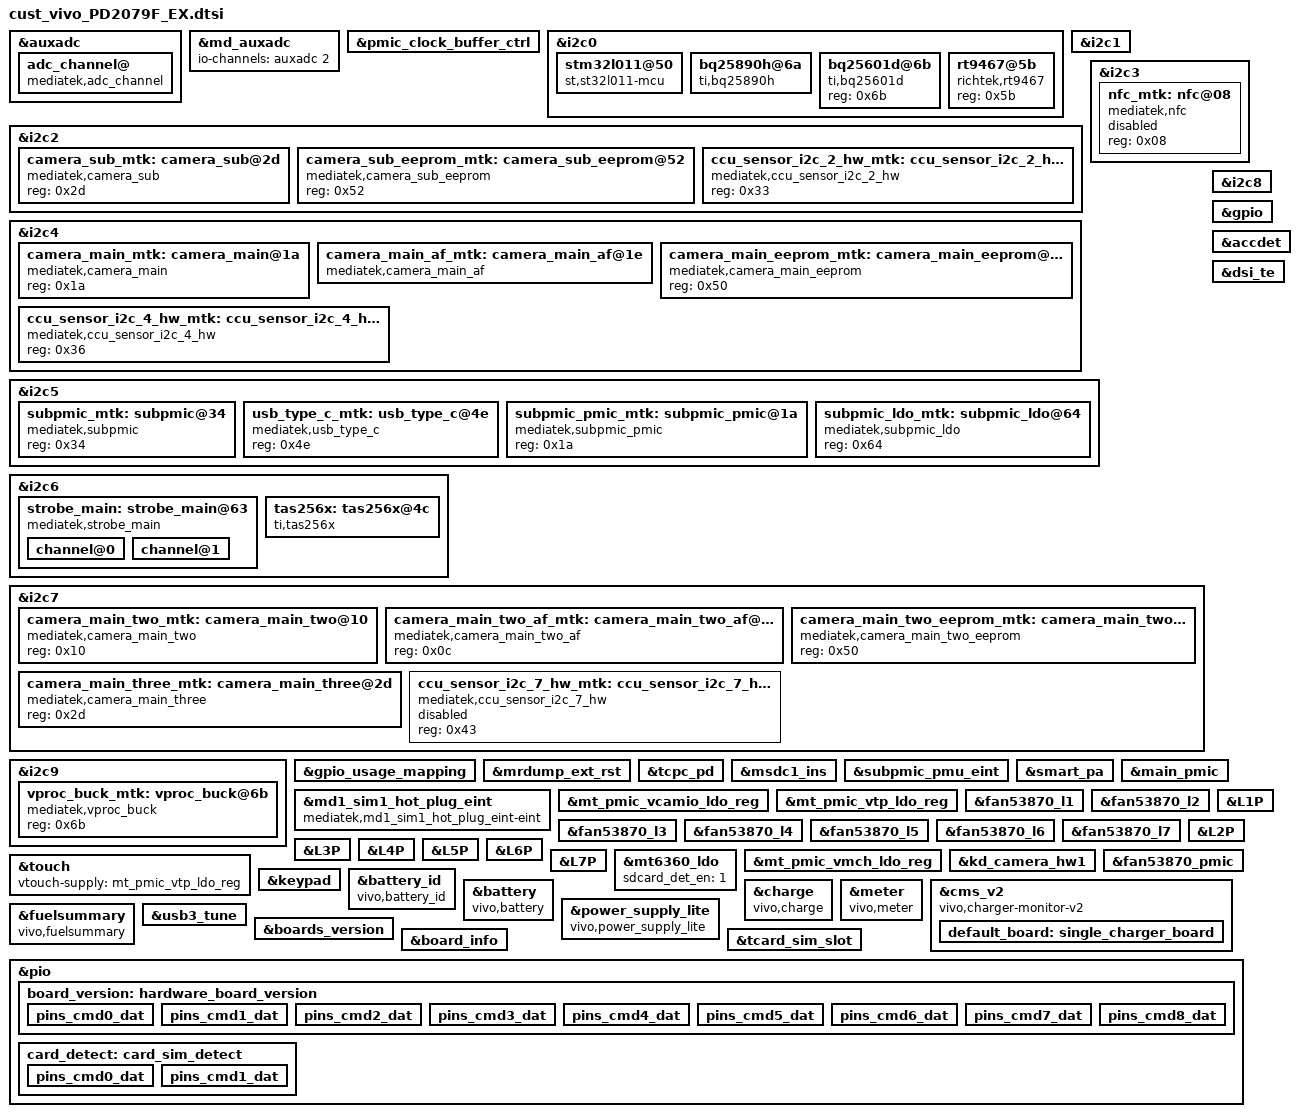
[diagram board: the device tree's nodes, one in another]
/*
 * Generated by MTK SP DrvGen Version: 3.5.160809 for MT6785.
 * 2020-11-23 11:59:31
 * Do Not Modify The File.
 * Copyright Mediatek Inc. (c) 2016.
*/

/*************************
 * ADC DTSI File
*************************/

&auxadc {
	adc_channel@ {
		compatible = "mediatek,adc_channel";
		mediatek,temperature0 = <0>;
		mediatek,temperature1 = <1>;
		mediatek,adc_fdd_rf_params_dynamic_custom_ch = <2>;
		status = "okay";
	};
};
&md_auxadc {
	io-channels = <&auxadc 2>;
};


/*************************
 * CLK_BUF DTSI File
*************************/

&pmic_clock_buffer_ctrl {
	mediatek,clkbuf-quantity = <7>;
	mediatek,clkbuf-config = <2 1 2 2 0 0 1>;
	mediatek,clkbuf-output-impedance = <4 4 4 4 0 0 4>;
	mediatek,clkbuf-controls-for-desense = <0 4 0 3 0 0 0>;
	status = "okay";
};


/*************************
 * I2C DTSI File
*************************/

&i2c0 {
	#address-cells = <1>;
	#size-cells = <0>;
	clock-frequency = <400000>;
	mediatek,use-open-drain;
};

&i2c1 {
	#address-cells = <1>;
	#size-cells = <0>;
	clock-frequency = <400000>;
	mediatek,use-open-drain;
};

&i2c2 {
	#address-cells = <1>;
	#size-cells = <0>;
	clock-frequency = <400000>;
	mediatek,use-open-drain;
	
	camera_sub_mtk:camera_sub@2d {
		compatible = "mediatek,camera_sub";
		reg = <0x2d>;
		status = "okay";
	};

	camera_sub_eeprom_mtk:camera_sub_eeprom@52 {
		compatible = "mediatek,camera_sub_eeprom";
		reg = <0x52>;
		status = "okay";
	};


	ccu_sensor_i2c_2_hw_mtk:ccu_sensor_i2c_2_hw@33 {
		compatible = "mediatek,ccu_sensor_i2c_2_hw";
		reg = <0x33>;
		status = "okay";
	};

};

&i2c3 {
	#address-cells = <1>;
	#size-cells = <0>;
	clock-frequency = <400000>;
	mediatek,use-open-drain;
	nfc_mtk:nfc@08 {
		compatible = "mediatek,nfc";
		reg = <0x08>;
		status = "disabled";
	};
	


	#include "fan53870.dtsi"
	#include "pm8008.dtsi"	

};

&i2c4 {
	#address-cells = <1>;
	#size-cells = <0>;
	clock-frequency = <1000000>;
	mediatek,use-open-drain;
	camera_main_mtk:camera_main@1a {
		compatible = "mediatek,camera_main";
		reg = <0x1a>;
		status = "okay";
	};

	camera_main_af_mtk:camera_main_af@1e {
		compatible = "mediatek,camera_main_af";
		reg = <0x1e>;
		status = "okay";
	};

	camera_main_eeprom_mtk:camera_main_eeprom@50 {
		compatible = "mediatek,camera_main_eeprom";
		reg = <0x50>;
		status = "okay";
	};



	ccu_sensor_i2c_4_hw_mtk:ccu_sensor_i2c_4_hw@36 {
		compatible = "mediatek,ccu_sensor_i2c_4_hw";
		reg = <0x36>;
		status = "okay";
	};

};

&i2c5 {
	#address-cells = <1>;
	#size-cells = <0>;
	clock-frequency = <3400000>;
	mediatek,use-push-pull;
	subpmic_mtk:subpmic@34 {
		compatible = "mediatek,subpmic";
		reg = <0x34>;
		status = "okay";
	};

	usb_type_c_mtk:usb_type_c@4e {
		compatible = "mediatek,usb_type_c";
		reg = <0x4e>;
		status = "okay";
	};

	subpmic_pmic_mtk:subpmic_pmic@1a {
		compatible = "mediatek,subpmic_pmic";
		reg = <0x1a>;
		status = "okay";
	};

	subpmic_ldo_mtk:subpmic_ldo@64 {
		compatible = "mediatek,subpmic_ldo";
		reg = <0x64>;
		status = "okay";
	};

};

/*
&i2c6 {
	#address-cells = <1>;
	#size-cells = <0>;
	clock-frequency = <400000>;
	mediatek,use-open-drain;
	i2c_lcd_bias_mtk:i2c_lcd_bias@73 {
		compatible = "mediatek,i2c_lcd_bias";
		reg = <0x73>;
		status = "okay";
	};

};
*/

&i2c6 {
	#address-cells = <1>;
	#size-cells = <0>;
	clock-frequency = <400000>;
	mediatek,use-open-drain;
	
	strobe_main: strobe_main@63 {
		compatible = "mediatek,strobe_main";
		reg = <0x63>;
		status = "okay";
	};
};

&i2c7 {
	#address-cells = <1>;
	#size-cells = <0>;
	clock-frequency = <400000>;
	mediatek,use-open-drain;
	
	camera_main_two_mtk:camera_main_two@10 {
		compatible = "mediatek,camera_main_two";
		reg = <0x10>;
		status = "okay";
	};

	camera_main_two_af_mtk:camera_main_two_af@0c {
		compatible = "mediatek,camera_main_two_af";
		reg = <0x0c>;
		status = "okay";
	};

	camera_main_two_eeprom_mtk:camera_main_two_eeprom@50 {
		compatible = "mediatek,camera_main_two_eeprom";
		reg = <0x50>;
		status = "okay";
	};

	camera_main_three_mtk:camera_main_three@2d {
		compatible = "mediatek,camera_main_three";
		reg = <0x2d>;
		status = "okay";
	};
	ccu_sensor_i2c_7_hw_mtk:ccu_sensor_i2c_7_hw@43 {
		compatible = "mediatek,ccu_sensor_i2c_7_hw";
		reg = <0x43>;
		status = "disabled";
	};

};

&i2c8 {
	#address-cells = <1>;
	#size-cells = <0>;
	clock-frequency = <400000>;
	mediatek,use-open-drain;
};

&i2c9 {
	#address-cells = <1>;
	#size-cells = <0>;
	clock-frequency = <3400000>;
	mediatek,use-open-drain;
	vproc_buck_mtk:vproc_buck@6b {
		compatible = "mediatek,vproc_buck";
		reg = <0x6b>;
		status = "okay";
	};

};



/*************************
 * GPIO DTSI File
*************************/

&gpio_usage_mapping {
	GPIO_FDD_BAND_SUPPORT_DETECT_1ST_PIN = <&pio 105 0>;
	GPIO_FDD_BAND_SUPPORT_DETECT_2ND_PIN = <&pio 106 0>;
	GPIO_FDD_BAND_SUPPORT_DETECT_3RD_PIN = <&pio 75 0>;
	GPIO_FDD_BAND_SUPPORT_DETECT_4TH_PIN = <&pio 107 0>;
	GPIO_SIM1_SIO = <&pio 128 0>;
	GPIO_SIM1_SRST = <&pio 129 0>;
	GPIO_SIM1_SCLK = <&pio 130 0>;
	GPIO_SIM2_SCLK = <&pio 131 0>;
	GPIO_SIM2_SRST = <&pio 132 0>;
	GPIO_SIM2_SIO = <&pio 133 0>;
	GPIO_SIM1_HOT_PLUG = <&pio 140 0>;
};

&gpio{
	gpio_init_default = <0 0 0 0 1 1 1>,
		<1 0 0 0 1 1 1>,
		<2 0 0 0 0 0 1>,
		<3 7 0 0 1 0 1>,
		<4 0 0 0 1 0 1>,
		<5 0 0 0 0 0 1>,
		<6 0 0 0 1 0 1>,
		<7 0 0 0 1 1 1>,
		<8 0 0 0 1 1 1>,
		<9 0 0 0 1 0 1>,
		<10 0 0 0 1 1 1>,
		<11 0 0 0 1 1 1>,
		<12 0 0 0 0 0 1>,
		<13 0 1 0 0 0 0>,
		<14 0 0 0 0 1 0>,
		<15 0 1 0 0 0 0>,
		<16 0 0 0 1 1 1>,
		<17 7 1 0 0 0 0>,
		<18 7 0 0 1 0 0>,
		<19 7 0 0 1 0 0>,
		<20 7 0 0 1 0 0>,
		<21 3 1 0 0 0 0>,
		<22 0 1 0 0 0 0>,
		<23 0 1 0 0 0 0>,
		<24 0 1 0 0 0 0>,
		<25 1 0 0 1 0 1>,
		<26 0 1 0 0 0 0>,
		<28 1 0 0 1 1 1>,
		<29 1 0 0 1 1 1>,
		<30 0 1 0 0 0 0>,
		<31 0 1 0 0 0 0>,
		<32 0 1 0 0 0 0>,
		<33 0 0 0 1 0 0>,
		<34 0 1 0 0 0 0>,
		<35 6 0 0 1 0 0>,
		<36 6 0 0 0 0 0>,
		<37 6 0 0 1 0 0>,
		<38 6 1 0 0 0 0>,
		<39 6 0 0 1 0 0>,
		<40 6 0 0 1 0 0>,
		<41 6 0 0 1 0 0>,
		<42 1 1 0 0 0 0>,
		<43 1 0 0 1 0 0>,
		<44 0 1 0 0 0 0>,
		<45 1 0 0 1 1 1>,
		<46 1 0 0 1 1 1>,
		<47 1 0 0 0 0 0>,
		<48 1 0 0 0 0 0>,
		<49 1 0 0 0 0 0>,
		<50 1 0 0 0 0 0>,
		<51 1 0 0 1 1 1>,
		<52 1 0 0 1 1 1>,
		<53 1 0 0 1 1 0>,
		<54 1 1 1 0 0 0>,
		<55 1 0 0 1 1 1>,
		<56 1 0 0 1 1 1>,
		<57 0 0 0 1 0 0>,
		<58 0 0 0 1 0 0>,
		<59 1 0 0 1 1 0>,
		<60 1 0 0 1 1 0>,
		<61 2 0 0 1 1 1>,
		<62 2 0 0 1 1 1>,
		<63 2 0 0 1 0 0>,
		<64 2 1 0 0 0 0>,
		<65 2 1 0 0 0 0>,
		<66 2 1 0 0 0 0>,
		<67 1 1 0 0 0 1>,
		<68 1 1 0 0 0 1>,
		<69 0 0 0 1 1 1>,
		<70 1 0 0 1 0 0>,
		<71 1 1 0 0 0 1>,
		<72 1 0 0 1 0 0>,
		<73 0 0 0 1 1 0>,
		<74 3 0 0 1 0 0>,
		<75 0 0 0 1 1 0>,
		<76 1 0 0 1 0 0>,
		<77 1 0 0 1 0 0>,
		<78 1 0 0 1 0 0>,
		<79 0 0 0 0 0 1>,
		<80 1 0 0 1 0 0>,
		<81 0 1 0 0 0 0>,
		<82 1 0 0 1 0 0>,
		<83 1 0 0 1 0 0>,
		<84 1 0 0 1 0 0>,
		<85 0 0 0 0 0 1>,
		<86 1 0 0 1 0 0>,
		<87 1 0 0 1 0 0>,
		<88 1 0 0 1 0 0>,
		<89 1 0 0 1 0 0>,
		<90 1 0 0 1 0 0>,
		<91 1 0 0 1 0 0>,
		<92 1 0 0 1 0 0>,
		<93 1 0 0 1 0 0>,
		<94 1 0 0 1 0 0>,
		<95 1 0 0 1 0 0>,
		<96 1 0 0 1 0 0>,
		<97 1 0 0 1 0 0>,
		<98 1 0 0 1 0 0>,
		<99 1 0 0 1 0 0>,
		<100 1 0 0 1 0 0>,
		<101 1 0 0 1 0 0>,
		<102 1 0 0 1 0 0>,
		<103 1 0 0 1 0 0>,
		<104 1 0 0 1 0 0>,
		<105 0 0 0 1 1 0>,
		<106 0 0 0 1 1 0>,
		<107 0 0 0 1 1 0>,
		<108 0 0 0 1 1 0>,
		<109 0 0 0 1 1 0>,
		<110 1 0 0 0 0 1>,
		<111 1 0 0 0 0 1>,
		<112 1 0 0 0 0 1>,
		<113 1 0 0 0 0 1>,
		<114 0 1 0 0 0 0>,
		<115 0 1 0 0 0 0>,
		<116 1 1 0 0 0 0>,
		<117 1 1 0 0 0 0>,
		<118 0 1 0 0 0 0>,
		<119 0 1 0 0 0 0>,
		<120 1 1 0 0 0 0>,
		<121 1 1 0 0 0 0>,
		<122 0 1 1 1 0 0>,
		<123 0 1 0 0 0 0>,
		<124 0 1 0 0 0 0>,
		<125 0 1 0 0 0 0>,
		<126 0 1 0 0 0 0>,
		<127 1 0 0 1 0 0>,
		<128 1 0 0 1 1 1>,
		<129 1 1 0 0 0 1>,
		<130 1 1 0 0 0 1>,
		<131 1 1 0 0 0 1>,
		<132 1 1 0 0 0 1>,
		<133 1 0 0 1 1 1>,
		<134 1 1 0 0 0 1>,
		<135 1 0 0 1 1 1>,
		<136 1 0 0 1 1 1>,
		<137 1 0 0 1 1 1>,
		<138 1 0 0 1 1 1>,
		<139 1 0 0 1 1 1>,
		<140 1 0 0 0 0 0>,
		<141 0 0 0 0 0 0>,
		<142 1 1 0 0 0 0>,
		<143 1 1 0 0 0 1>,
		<144 1 1 0 0 0 1>,
		<145 1 1 0 0 0 1>,
		<146 1 0 0 1 0 1>,
		<147 0 0 0 1 0 0>,
		<148 0 0 0 1 1 0>,
		<149 0 0 0 1 1 0>,
		<150 1 0 0 1 0 0>,
		<151 1 0 0 1 1 1>,
		<152 1 0 0 1 1 1>,
		<153 1 0 0 1 0 0>,
		<154 0 0 0 1 0 0>,
		<155 0 1 0 0 0 0>,
		<156 0 1 0 0 0 0>,
		<157 0 1 0 0 0 0>,
		<158 0 1 0 0 0 0>,
		<159 0 1 0 0 0 0>,
		<160 0 1 0 0 0 0>,
		<161 0 1 0 0 0 0>,
		<162 0 1 0 0 0 0>,
		<163 0 1 0 0 0 0>,
		<164 0 1 0 0 0 0>,
		<165 1 0 0 1 0 0>,
		<166 1 0 0 1 0 0>,
		<167 0 1 0 1 1 0>,
		<179 1 0 0 1 0 0>,
		<180 1 0 0 1 0 0>,
		<181 1 1 0 0 0 0>,
		<182 1 1 0 0 0 0>,
		<183 1 1 0 0 0 0>,
		<184 1 0 0 1 0 0>,
		<185 1 1 0 0 0 0>,
		<186 1 0 0 1 0 0>,
		<187 1 1 0 0 0 0>,
		<188 1 0 0 1 0 1>,
		<189 1 1 0 0 0 1>,
		<190 1 1 0 0 0 1>,
		<191 1 1 0 0 0 1>,
		<192 1 1 0 0 0 1>,
		<193 1 0 0 1 0 1>,
		<194 1 0 0 1 0 1>,
		<195 0 1 0 0 0 0>,
		<196 1 1 0 0 0 0>,
		<197 0 1 0 0 0 0>,
		<198 1 0 0 0 0 1>,
		<199 1 0 0 0 0 1>,
		<200 1 0 0 1 1 0>,
		<201 1 1 0 0 0 0>,
		<202 0 1 0 0 0 0>,
		<203 0 0 0 1 0 0>,
		<204 0 0 0 1 0 0>,
		<205 0 0 0 1 0 0>,
		<206 0 0 0 1 0 0>,
		<207 0 0 0 1 0 0>,
		<208 0 0 0 1 0 0>,
		<209 0 0 0 1 0 0>,
		<210 0 0 0 1 0 0>;
};


/*************************
 * EINT DTSI File
*************************/

#include <dt-bindings/interrupt-controller/irq.h>
#include <dt-bindings/interrupt-controller/arm-gic.h>

&mrdump_ext_rst {
	interrupt-parent = <&pio>;
	interrupts = <0 IRQ_TYPE_LEVEL_LOW 0 0>;
	deb-gpios = <&pio 0 0>;
	debounce = <512000>;
	status = "okay";
};

&accdet {
	interrupt-parent = <&pio>;
	interrupts = <9 IRQ_TYPE_LEVEL_LOW 9 0>,
					<1 IRQ_TYPE_LEVEL_LOW 1 0>;
	deb-gpios = <&pio 9 0>;
	deb-rgpios = <&pio 1 0>;
	debounce = <256000>;
	debounce1 = <256000>;
	status = "okay";
};

/*
&touch {
	interrupt-parent = <&pio>;
	interrupts = <1 IRQ_TYPE_EDGE_FALLING 1 0>;
	status = "okay";
};
*/

&tcpc_pd {
	interrupt-parent = <&pio>;
	interrupts = <7 IRQ_TYPE_EDGE_FALLING 7 0>;
	status = "okay";
};

&msdc1_ins {
	interrupt-parent = <&pio>;
	interrupts = <8 IRQ_TYPE_LEVEL_LOW 8 0>;
	status = "okay";
};

/*
&goodix_fp {
	interrupt-parent = <&pio>;
	interrupts = <3 IRQ_TYPE_EDGE_RISING 3 0>;
	status = "okay";
};
*/

&subpmic_pmu_eint {
	interrupt-parent = <&pio>;
	interrupts = <16 IRQ_TYPE_EDGE_FALLING 16 0>;
	status = "okay";
};

&dsi_te {
	interrupt-parent = <&pio>;
	interrupts = <43 IRQ_TYPE_EDGE_RISING 43 1>;
	status = "okay";
};

&smart_pa {
	interrupt-parent = <&pio>;
	interrupts = <69 IRQ_TYPE_LEVEL_LOW 69 0>;
	status = "okay";
};

&main_pmic {
	interrupt-parent = <&pio>;
	interrupts = <193 IRQ_TYPE_LEVEL_HIGH 209 0>;
	status = "okay";
};



/*************************
 * MD1_EINT DTSI File
*************************/

&md1_sim1_hot_plug_eint {
	compatible = "mediatek,md1_sim1_hot_plug_eint-eint";
	interrupts = <0 8>;
	debounce = <0 100000>;
	dedicated = <0 0>;
	src_pin = <0 1>;
	sockettype = <0 0>;
	status = "okay";
};



/*************************
 * PMIC DTSI File
*************************/

&mt_pmic_vcamio_ldo_reg {
	regulator-name = "vcamio";
	regulator-default-on = <1>; /* 0:skip, 1: off, 2:on */
	status = "okay";
};
&mt_pmic_vtp_ldo_reg {
	regulator-name = "vtp";
	regulator-default-on = <1>; /* 0:skip, 1: off, 2:on */
	status = "okay";
};
/* hope add fan53870 pmic start*/
&fan53870_l1 {
	regulator-name = "fan53870_l1";
	regulator-default-on = <1>; /* 0:skip, 1: off, 2:on */
	status = "okay";
};

&fan53870_l2 {
	regulator-name = "fan53870_l2";
	regulator-default-on = <1>; /* 0:skip, 1: off, 2:on */
	status = "okay";
};

&fan53870_l3 {
	regulator-name = "fan53870_l3";
	regulator-default-on = <1>; /* 0:skip, 1: off, 2:on */
	status = "okay";
};

&fan53870_l4 {
	regulator-name = "fan53870_l4";
	regulator-default-on = <1>; /* 0:skip, 1: off, 2:on */
	status = "okay";
};

&fan53870_l5 {
	regulator-name = "fan53870_l5";
	regulator-default-on = <1>; /* 0:skip, 1: off, 2:on */
	status = "okay";
};

&fan53870_l6 {
	regulator-name = "fan53870_l6";
	regulator-default-on = <1>; /* 0:skip, 1: off, 2:on */
	status = "okay";
};

&fan53870_l7 {
	regulator-name = "fan53870_l7";
	regulator-default-on = <1>; /* 0:skip, 1: off, 2:on */
	status = "okay";
};
/* hope add fan53870 pmic end*/

/* hope add pm8008 pmic start*/
&L1P {
	regulator-name = "pm8008_l1";
	regulator-default-on = <1>; /* 0:skip, 1: off, 2:on */
	status = "okay";

};

&L2P {
	regulator-name = "pm8008_l2";
	regulator-default-on = <1>; /* 0:skip, 1: off, 2:on */
	status = "okay";

};

&L3P {
	regulator-name = "pm8008_l3";
	regulator-default-on = <1>; /* 0:skip, 1: off, 2:on */
	status = "okay";

};

&L4P {
	regulator-name = "pm8008_l4";
	regulator-default-on = <1>; /* 0:skip, 1: off, 2:on */
	status = "okay";

};

&L5P {
	regulator-name = "pm8008_l5";
	regulator-default-on = <1>; /* 0:skip, 1: off, 2:on */
	status = "okay";

};

&L6P {
	regulator-name = "pm8008_l6";
	regulator-default-on = <1>; /* 0:skip, 1: off, 2:on */
	status = "okay";

};

&L7P {
	regulator-name = "pm8008_l7";
	regulator-default-on = <1>; /* 0:skip, 1: off, 2:on */
	status = "okay";

};
/* hope add pm8008 pmic end*/

/* hope add for mt6360 LDO5 use for af power, remove sdcard use LDO5 PMIC start */
&mt6360_ldo {
	sdcard_det_en = <1>;
};
&mt_pmic_vmch_ldo_reg {
	regulator-name = "VMCH";
	regulator-default-on = <1>; /* 0:skip, 1: off, 2:on */
	status = "okay";
};
/* hope add for mt6360 LDO5 use for af power, remove sdcard use LDO5 PMIC end */

&kd_camera_hw1 {
 
 	cam0_vcamio-supply = <&mt_pmic_vcamio_ldo_reg>;
	cam0_vcamd-supply = <&fan53870_l1>;
	cam0_vcamd_b-supply = <&L1P>;
	cam0_vcama-supply = <&fan53870_l3>;
	cam0_vcama_b-supply = <&L3P>;
	//cam0_vcamois-supply = <&fan53870_l6>;
	//cam0_vcamois_b-supply = <&L6P>;	
		
	cam1_vcamio-supply = <&mt_pmic_vcamio_ldo_reg>;
	cam1_vcamd-supply = <&fan53870_l2>;
	cam1_vcamd_b-supply = <&L2P>;
	cam1_vcama-supply = <&fan53870_l4>;
	cam1_vcama_b-supply = <&L4P>;
		
	cam2_vcamio-supply = <&mt_pmic_vcamio_ldo_reg>;
	cam2_vcama-supply = <&fan53870_l5>;
 	cam2_vcama_b-supply = <&L5P>;
	
	cam4_vcamio-supply = <&mt_pmic_vcamio_ldo_reg>;
	cam4_vcama-supply = <&fan53870_l5>;
	cam4_vcama_b-supply = <&L5P>;
		
	cam0_enable_sensor = "s5kgw3sp13pd2062_mipi_raw";
	cam1_enable_sensor = "s5kgh1sm24pd2062_mipi_raw";
        cam2_enable_sensor = "ov8856pd2062_mipi_raw";
        cam4_enable_sensor = "ov02b10pd2062_mipi_raw";
 
	status = "okay";
};

&fan53870_pmic {
	interrupt-parent = <&pio>;
	interrupts = <14 IRQ_TYPE_EDGE_RISING 14 0>;
	deb-gpios = <&pio 14 0>;
	debounce = <256000>;
	status = "okay";
};

&camera_main_af_mtk {
	vcamaf-supply = <&fan53870_l6>;
};
&strobe_main {
	decouple = <0>;
	channel@0 {
		type = <1>;
		ct = <0>;
		part = <0>;
	};
	channel@1 {
		type = <1>;
		ct = <1>;
		part = <0>;
	};
};


&touch {
	vtouch-supply = <&mt_pmic_vtp_ldo_reg>;
	status = "okay";
};


/*************************
 * POWER DTSI File
*************************/



/*************************
 * KPD DTSI File
*************************/

&keypad {
	mediatek,kpd-key-debounce = <1024>;
	mediatek,kpd-sw-pwrkey = <116>;
	mediatek,kpd-hw-pwrkey = <8>;
	mediatek,kpd-sw-rstkey  = <114>;
	mediatek,kpd-hw-rstkey = <17>;
	mediatek,kpd-use-extend-type = <0>;
	/*HW Keycode [0~71] -> Linux Keycode*/
	mediatek,kpd-hw-map-num = <72>;
	mediatek,kpd-hw-init-map = <115 0 0 0 0 0 0 0 0 0 0 0 0 0 0 0 0 0 0 0 0 0 0 0 0 0 0 0 0 0 0 0 0 0 0 0 0 0 0 0 0 0 0 0 0 0 0 0 0 0 0 0 0 0 0 0 0 0 0 0 0 0 0 0 0 0 0 0 0 0 0 0 >;
	mediatek,kpd-pwrkey-eint-gpio = <0>;
	mediatek,kpd-pwkey-gpio-din  = <0>;
	mediatek,kpd-hw-dl-key0 = <17>;
	mediatek,kpd-hw-dl-key1 = <0>;
	mediatek,kpd-hw-dl-key2 = <8>;
	mediatek,kpd-hw-recovery-key = <17>;
	mediatek,kpd-hw-factory-key = <0>;
	status = "okay";
};


/* fuxi add for battery&charge start */
&battery_id {
	status = "okay";
	compatible = "vivo,battery_id";

	vivo,bat-adc-ctrl-gpio = <&pio 202 0>;

	io-channels = <&auxadc 3>;
	io-channel-names = "battery_id_adc";

	vivo,bat-name = "B-O5 LW 5000","B-O5 LW 5000","B-O5 SDI 5000","B-O5 ATL 5000","UNKOWN","UNKOWN";
};

&battery {
	status = "okay";
	compatible = "vivo,battery";

	io-channels = <&auxadc 0>,
		<&auxadc 1>,
		<&auxadc 2>;
	io-channel-names = "primary_board_therm",
		"pa_therm",
		"parallel_board_therm";

	vivo,low-volt-threshold = <3400>;
	vivo,soft-rise-percent = <92>;
	vivo,soft-rise-cumulative = <10>;
	vivo,soft-rise-keep-cumulative = <14>;
	vivo,percnet-sync-delta = <4>;
	vivo,percnet-sync-cumulative = <9>;
	vivo,full-sync-cumulative = <3>;
	vivo,soft-term-percent = <99>;
	vivo,soft-term-cumulative = <48>;
};

&charge {
	status = "okay";
	compatible = "vivo,charge";

	vivo,chg-wdt-s = <40>;
	vivo,re-chg-voltage-mv = <100>;
	vivo,prechg-voltage-mv = <3000>;
	vivo,iprechg-current-ma = <300>;
	vivo,iterm-current-ma = <256>;
	vivo,vreg-voltage-mv = <4430>;
	vivo,vindpm-voltage-mv = <4600>;
	vivo,sys-voltage-min-mv= <3300>;
	vivo,boostv-voltage-mv = <5150>;
	vivo,boostv-ilimit-ma = <1500>;
	vivo,ovp-voltage-mv = <15000>;

	vivo,battery-id-vreg-mv = <4430 4430 4430 4430 4430 4430>;
	/*
	 * 0  auto detect charging
	 * 1  vivo-normal chargine
	 * 2  vivo-single engine charging
	 * 3  vivo-dual engine charging
	 * 4  vivo-flash charging
	*/
	vivo,charge-scheme = <0>;
	vivo,direct-charger-enable;

	/*
	 * SUPPORTED_ADAPTER_DEFAULT = 0,
	 * SUPPORTED_ADAPTER_VIVO_LV_DCHG_5V_4500MA = 1,
	 * SUPPORTED_ADAPTER_VIVO_HV_DCHG_10V_2250MA = 2,
	 * SUPPORTED_ADAPTER_QC20__9V_2000MA = 3,
	 * SUPPORTED_ADAPTER_VIVO_HV_DCHG_10V_4000MA = 4,
	 * SUPPORTED_ADAPTER_MAX,
	 */
	vivo,supported-adapter = <3>;

	//parameter for 9V2A
	vivo,primary-ichg-max-ma = <2000>;
	vivo,parallel-ichg-max-ma = <1500>;

	vivo,flashchg-spec-ma = <2000 3300 6000>;
	vivo,fastchg-spec-ma = <2000 2100 3800>;
	vivo,normalchg-spec-ma = <2000 1500 2300>;

	/* 0---PMIC; 1---CHGIC */
	vivo,vbus-detect-source = <1>;

	//vivo,usboe-gpio = <&pio 178 0>;

	/*ffc*/
	//vivo,ffc-enable;
	vivo,ffc-iterm-ma = <(-750)>;
	vivo,ffc-vreg-mv = <4500>;
	vivo,battery-id-ffc-vreg-mv = <4500 4500 4500 4492 4500 4500>;
	vivo,ffc-temperature-range = <150 450>;
	vivo,ffc-full-vbat-table-size = <3>;
	vivo,ffc-full-vbat-table = <4498 4500 4490>;
	vivo,ffc-full-ibat-table-size = <2>;
	vivo,ffc-full-ibat-table = <150 349 (-980)>,
		<350 449 (-1176)>;
	vivo,battery-id-ffc-full-ibat-table = <(-980) (-785) (-785) (-499) (-785) (-785)>,
		<(-980) (-1176) (-1099) (-658) (-1099) (-1099)>,
		<(-1176) (-1176) (-1178) (-758) (-1178) (-1178)>;
};

&meter {
	status = "okay";
	compatible = "vivo,meter";

	vivo,load-capacity-delta-max = <60>;
	vivo,poweron-delta-capacity = <20>;
	vivo,poweron-low-capacity = <3>;
	vivo,volt-car-delta = <8>;
	vivo,car-volt-delta = <6>;
	vivo,meter-res-compesate = <10>;
	vivo,ocv-board-compesate = <0>;

	/* 0---AGING_UNSUPPORTED; 1---DRIVER_SUPPORTED; 2---USPACE_SUPPORTED */
	vivo,battery-aging-support = <2>;

	vivo,capacity-mAh = <3990>;
	/*COLD_CHG COLD_DISCHG NORMAL_CHG NORMAL_DISCHG*/
	vivo,car-tune-value = <1045 1000 1045 1000>,
		<1045 1000 1045 1000>,
		<1045 1000 1045 1000>,
		<1045 1000 1045 1000>,
		<1045 1000 1045 1000>,
		<1045 1000 1045 1000>;
	vivo,bats-qmax = <3505 3677 3750 3857 3880>,
		<3600 4290 4560 4780 4850>,
		<3180 3300 4200 4740 4810>,
		<4000 4300 4580 4780 4830>,
		<4500 4668 4762 4851 4821>,
		<4500 4668 4762 4851 4821>;

	/* car-tune adjust remap */
	vivo,car-tune-adjust-enable;
	vivo,car-tune-adjust-size = <3>;
	vivo,car-tune-adjust-table = <0 10 (360) 6>,
		<11 20 (-35) 7>,
		<21 100 (-45) 8>;

	#include "bat_setting/PD2066_battery_table.dtsi"
};

&cms_v2 {
	compatible = "vivo,charger-monitor-v2";
	status = "okay";

	default_board: single_charger_board {
		/*default board: keep in xxxxxx*/
		support-board-version = "xxxxxx";

		vivo,bat-det-method = <0>;//r:0, rc:1, eprom:2, ex-fg:3
		vivo,bat-id-gpio = <&pio 159 0>;

		//vivo,no-bat-warning;
		//vivo,no-chg-timeout;
		vivo,chg-timeout-mins = <600>;

		//high temperature charger current control enable
		vivo,htccc-enable;
		vivo,htccc-data = <46 55 4100000 100000>;

		//vivo,fbon-scale-enable;/*disable default*/
		vivo,fbon-scale-data = <2 100 100>;

		//vivo,switch-scale-enable;/*disable from rom4.0*/
		vivo,switch-scale-data = <75 53>;

		vivo,calling-scale-enable;
		vivo,calling-scale-data = <100 21>;/*ibat:3900 * 0.54 = 2106,more than 1500,not exit dchg*/
		vivo,calling-dchg-disable;

		vivo,weixin-calling-scale-enable;
		vivo,weixin-calling-scale-data = <100 112>;/*5000mA*/

		//vivo,fixed-scale-enable;
		vivo,fixed-scale-data = <120 3800 0>;/*dchg fixed time adjust the max ibat,disable default*/

		/*data processing : batt-temp*/
		vivo,dp-batt-temp-enable;
		vivo,dp-batt-temp-data = <100>;

		/* charging current for devices in exhibition mode */
		vivo,exhibition-mode-current-primary = <2048>;
		vivo,exhibition-mode-current-parallel = <0>;

		/*default tc parameter*/
		//single charger ibat scale base on temperature battery cell info:1C/1.2C 3960mah
		/* tmin, tmax, data, volt1, data_ex1, volt2, data_ex2. */
		vivo,normal-tc-row-col = <10 7>;
		vivo,normal-tc-data = <550 8888 0 0 0 0 0>,
			<450 549 50 0 0 0 0>,
			<200 449 100 4200000 70 0 0>,
			<150 199 70 0 0 0 0>,
			<100 149 70 4200000 50 0 0>,
			<50 99 30 0 0 0 0>,
			<0 49 30 0 0 0 0>,
			<(-8888) (-1) 0 0 0 0 0>,
			<(-8888) (-1) 0 0 0 0 0>,
			<(-8888) (-1) 0 0 0 0 0>;

		/*flash tc parameter*/
		vivo,flash-normal-tc-row-col = <10 7>;
		vivo,flash-normal-tc-data = <550 8888 0 0 0 0 0>,
			<450 549 50 0 0 0 0>,
			<200 449 223 4390000 179 4400000 134>,
			<150 199 203 4250000 152 0 0>,
			<100 149 120 4200000 100 0 0>,
			<50 99 70 4200000 50 0 0>,
			<0 49 50 4380000 50 0 0>,
			<(-50) (-1) 30 0 0 0 0>,
			<(-100) (-51) 20 0 0 0 0>,
			<(-8888) (-101) 0 0 0 0 0>;

		/*adjust fastchg base on board temperature and fb off*/
		vivo,intell-charge-enable;
		vivo,parallel-temp-enable = <1 1>;//<x y> x:fb-on y:fb-off

		/* Flash charge fb-on intell param */
		vivo,primary-fbon-tc-row-col = <6 3>;
		vivo,primary-fbon-tc-data = <460 8888 1600>,
			<410 459 2600>,
			<400 409 3000>,
			<390 399 3300>,
			<371 389 3700>,
			<(-8888) 370 6000>;

		vivo,parallel-fbon-tc-row-col = <1 3>;
		vivo,parallel-fbon-tc-data = <(-8888) 8888 0>;


		/* Flash charge fb-off intell param */
		vivo,primary-fboff-tc-row-col = <6 3>;
		vivo,primary-fboff-tc-data = <450 8888 1800>,
			<390 449 3000>,
			<380 389 3400>,
			<376 379 3700>,
			<371 375 4100>,
			<(-8888) 370 6000>;
		vivo,parallel-fboff-tc-row-col = <1 3>;
		vivo,parallel-fboff-tc-data = <(-8888) 8888 0>;

		/* 9v Fast charge fb-on intell param */
		vivo,9v-primary-fbon-tc-row-col = <6 3>;
		vivo,9v-primary-fbon-tc-data = <441 8888 512>,
			<421 440 800>,
			<411 420 900>,
			<401 410 1000>,
			<391 400 1200>,
			<(-8888) 390 1400>;
		vivo,9v-parallel-fbon-tc-row-col = <4 3>;
		vivo,9v-parallel-fbon-tc-data = <411 8888 512>,
			<391 410 650>,
			<381 390 800>,
			<(-8888) 380 1000>;
		// second parallel parameter, for rt9467
		vivo,9v-2nd-parallel-fbon-tc-row-col = <4 3>;
		vivo,9v-2nd-parallel-fbon-tc-data = <411 8888 512>,
			<391 410 650>,
			<381 390 800>,
			<(-8888) 380 1000>;

		/* 9v Fast charge fb-off intell param */
		vivo,9v-primary-fboff-tc-row-col = <7 3>;
		vivo,9v-primary-fboff-tc-data = <451 8888 512>,
			<431 450 1024>,
			<411 430 1152>,
			<391 410 1344>,
			<371 390 1536>,
			<361 370 1856>,
			<(-8888) 360 2048>;
		vivo,9v-parallel-fboff-tc-row-col = <6 3>;
		vivo,9v-parallel-fboff-tc-data = <431 8888 480>,
			<411 430 800>,
			<391 410 1200>,
			<371 390 1300>,
			<361 370 1400>,
			<(-8888) 360 1500>;
		// second parallel parameter, for rt9467
		vivo,9v-2nd-parallel-fboff-tc-row-col = <6 3>;
		vivo,9v-2nd-parallel-fboff-tc-data = <431 8888 480>,
			<411 430 800>,
			<391 410 900>,
			<371 390 1250>,
			<361 370 1400>,
			<(-8888) 360 1500>;


		/* 5v Normal charge fb-on intell param */
		vivo,5v-primary-fbon-tc-row-col = <7 3>;
		vivo,5v-primary-fbon-tc-data = <491 8888 512>,
			<471 490 1024>,
			<451 470 1216>,
			<431 450 1408>,
			<411 430 1600>,
			<381 410 1800>,
			<(-8888) 380 2048>;
		vivo,5v-parallel-fbon-tc-row-col = <1 3>;
		vivo,5v-parallel-fbon-tc-data = <(-8888) 8888 0>;

		/* 5v Normal charge fb-off intell param */
		vivo,5v-primary-fboff-tc-row-col = <6 3>;
		vivo,5v-primary-fboff-tc-data = <491 8888 512>,
			<471 490 1024>,
			<451 470 1216>,
			<431 450 1600>,
			<411 430 1800>,
			<(-8888) 410 2304>;
		vivo,5v-parallel-fboff-tc-row-col = <1 3>;
		vivo,5v-parallel-fboff-tc-data = <(-8888) 8888 0>;

		// Direct charging param
		vivo,direct-charger-enable;//porting_check
		vivo,ex-bms-psy-name = "bq_bms";

		// bat_baord, usb_conn, pcb_conn(master_bat_conn), bat_conn
		vivo,dchg-ntc-protect-enable;
		vivo,dchg-ntc-protect-data = <750 800 850 850>;

		vivo,adapter-cooldown-data = <900 850 3400>;
		/*adapter power derate*/
		vivo,adapter-power-derate-enable;

		/* usb connecter protect param
		 * USB_PROTECT_NONE = 0,
		 * USB_CONN_TEMP_HEAT_PROTECT = BIT(0),
		 * USB_ID_PROTECT = BIT(1),
		 */
		vivo,usb-connecter-protect-enable = <1>;
		vivo,usb-id-protect-data= <1100 1547 500>;/* 500K, 2M, fcc */
		vivo,usb-conn-heat-protect-data-row-col = <2 4>;
		vivo,usb-conn-heat-protect-data= <260 8888 670 620>,
			<(-8888) 259 570 520>;

		/*
		 * max vbus of adapter:11v, max ibus of adapter:5A
		 * min voltage of battery for half chg:3500mV,max voltage of battery for half charge:4100mV,
		 * 5V2A charge min current threshold: 1000mA,5V2A charge max current threshold:2100mA,
		 * flash charge min current threshold:5000mA,flash charge max current threshold:11000mA
		 */

		/*default parameter*/
		vivo,charge-param-judge-threshold = <9 2 3500 4300 1000 2100 2100 4600>;
		/* factory mode charging test param */
		vivo,charge-test-param-row-col = <12 3>;
		vivo,charge-test-param-data = <0 0 5500>, /* cable resistance, min value, max value */
		        <0 0 5500>, /* master ibus, min ibus, max ibus */
		        <0 0 5500>, /* slave ibus, min ibus, max ibus */
		        <1 20 40>, /* batt therm ntc, min value, max value */
		        <1 20 45>, /* board therm ntc, min value, max value */
		        <0 20 50>, /* sub charger ntc, min value, max value */
		        <0 20 45>, /* usb con ntc, min value, max value */
		        <0 20 45>, /* usb con 1 ntc, double usb NTC, min value, max value */
		        <0 20 45>, /* bat btb master ntc, min value, max value */
		        <0 20 50>, /* bat btb sub ntc, min value, max value */
		        <0 20 50>, /* bat board ntc, min value, max value */
		        <0 20 50>; /* wireless charge coil ntc, min value, max value */

		/*flash parameter*/
		vivo,flash-charge-param-judge-threshold = <11 3 3500 4100 1000 2200 4000 6100>;
		/* factory mode charging test param */
		vivo,flash-charge-test-param-row-col = <12 3>;
		vivo,flash-charge-test-param-data = <1 0 5500>, /* cable resistance, min value, max value */
		        <1 0 5500>, /* master ibus, min ibus, max ibus */
		        <0 0 5500>, /* slave ibus, min ibus, max ibus */
		        <1 20 40>, /* batt therm ntc, min value, max value */
		        <1 20 45>, /* board therm ntc, min value, max value */
		        <0 20 50>, /* sub charger ntc, min value, max value */
		        <1 20 45>, /* usb con ntc, min value, max value */
		        <0 20 45>, /* usb con 1 ntc, double usb NTC, min value, max value */
		        <1 20 45>, /* bat btb master ntc, min value, max value */
		        <0 20 50>, /* bat btb sub ntc, min value, max value */
		        <0 20 50>, /* bat board ntc, min value, max value */
		        <0 20 50>; /* wireless charge coil ntc, min value, max value */
	};
};

&power_supply_lite {
	status = "okay";
	compatible = "vivo,power_supply_lite";
};

&fuelsummary {
	status = "okay";
	compatible = "vivo,fuelsummary";

	/************************************************************
	 *
	 *  0   vivo-fastchg
	 *  1   qcom-dualchg
	 *  2   mtk-dualchg
	 *  3   qcom-normchg
	 *  4   mtk-normchg
	 *
	 ***********************************************************/
	chg-scheme = <2>;
	fex-version = <3>;
	fbon-ibat = <(-900)>;
	fboff-ibat = <(-1000)>;

	/* 0---AGING_UNSUPPORTED; 1---DRIVER_SUPPORTED; 2---USPACE_SUPPORTED */
	vivo,battery-aging-support = <2>;
};

&i2c0 {
	#address-cells = <1>;
	#size-cells = <0>;
	status = "okay";
	clock-frequency = <100000>;

	stm32l011@50 {
		compatible = "st,st32l011-mcu";
		reg = <0x50>;

		//vpower-ldo-supply = <&mt_pmic_vcn33_2_wifi_ldo_reg>;
		vivo,power-gpio = <&pio 24 0>;//ZC_LDO_EN
		vivo,int-gpio = <&pio 13 0>;//MCU_INT_AP
		vivo,usbsel-gpio = <&pio 23 0>;//USB_SW_EN
		vivo,shift-en-gpio = <&pio 80 0>;//SHIFT_EN
		//vivo,chg-version-gpio = <&pio 64 0>;//
		//vivo,sbu-pwr-gpio = <&pio 20 0>;
		ti,temp-cold-degc = <2>;
		ti,temp-hot-degc = <43>;
		vivo,total-limit-max-ma = <6000>;
		vivo,bigdata-collect-time-limit = <95>;//seconds
		vivo,direct-charger-enable;//porting_check

		/*FFC charge: */
		vivo,ffc-support;
		vivo,ffc-temperature-range = <150 450>;
		//vivo,ffc-param-tuning-enable = <1963>;
		vivo,ffc-cc-to-cv-ibat-thr-rc = <1 3>;
		/*<Tmin Tmax current>*/
		vivo,ffc-cc-to-cv-ibat-thr-table = <150 450 4900>;
		vivo,ffc-dchg-cv-mv-rc = <3 2>;
		/*btb_cv,fg_cv*/
		vivo,ffc-dchg-cv-mv-table = <4450 4430>,/*default*/
			<4535 4535>,/*single_charging*/
			<4500 4480>;/*dual_charging*/
		vivo,battery-id-ffc-dchg-btb_cv-mv-table = <4535 4508 4508 4508 4508 4508>;
		vivo,battery-id-ffc-dchg-fg_cv-mv-table = <4535 4500 4500 4492 4500 4500>;

		//vivo,cout-int-gpio = <&pio 5 0>;

		vivo,sbu-cable-id-detect-enable;

		vivo,bat-board-temp-enable = <0>;
		vivo,usb-conn-temp-enable = <1>;
		vivo,bat-conn-temp-enable = <1>;

		vivo,master-bat-conn-temp-enable = <2>;
		vivo,dchg-exit-ntc-threshold = <700 650 700 700 1200>;

		/* BQ25970_SINGLE_DCHG:
		 * DCHG_SINGLE_TYPE_22P5W = 0,
		 * DCHG_SINGLE_TYPE_33W = 1,
		 * DCHG_SINGLE_TYPE_44W = 2,
		 * BQ25970_DUAL_DCHG:DCHG_DUAL_TYPE_44W = 3,
		 */
		vivo,dchg-supported-type = <1>;
		/*adapter power derate*/
		vivo,adapter-power-derate-enable;

		//vivo,single-charger-enable;
		vivo,adapter-sha-encryption;

		io-channels = <&auxadc 4>,
			<&auxadc 5>;

		io-channel-names = "sbu2_cable_id_adc",
			"sbu1_cable_id_adc";

		/*cable r limit table :
		  <rmin,rmax, dchg_ibus_max, cable_id_type, limit_count>
		  cable_id_type: 0:effective cable id, 1:other(default) cable id
		 */
		vivo,cable-r-limit-table-rc = <8 5>;
		vivo,cable-r-limit-table = <(-8888) 380 3000 0 0>,
			<381 444 2250 0 0>,
			<445 555 1800 0 0>,
			<556 8888 0 0 0>,
			<(-8888) 380 3000 1 0>,
			<381 444 2250 1 0>,
			<445 555 1800 1 0>,
			<556 8888 0 1 0>;

		/*load firmware profile*/
		vivo,fw-id-range-pct = <100>;
		#include "bat_setting/mcu-firmware-data-33w.dtsi"
		#include "bat_setting/mcu-firmware-data-44w.dtsi"
	};

	bq25890h@6a {
		compatible = "ti,bq25890h";
		reg = <0x6a>;

		vivo,int-gpio = <&pio 16 0>;
	};

	bq25601d@6b {
		compatible = "ti,bq25601d";
		reg = <0x6b>;

		//vivo,int-gpio = <&pio 20 0>;
		//vivo,enable-gpio = <&pio 166 0>;
	};

	rt9467@5b {
		compatible = "richtek,rt9467";
		reg = <0x5b>;

		//vivo,int-gpio = <&pio 3 0>;//main ic second

		//vivo,int-gpio = <&pio 20 0>;
		//vivo,enable-gpio = <&pio 166 0>;
	};
};
/* fuxi add for battery&charge end */

/*vivo audio team add for speaker begin*/
&i2c6{
	tas256x:tas256x@4c {
		compatible = "ti,tas256x";
		reg = <0x4c>;
		ti,left-channel = <0x4c>;
		ti,channels = <1>; /* channel number */
		ti,reset-gpio = <&pio 127 0>;
		ti,irq-gpio = <&pio 69 0>;

		ti,iv-width = <16>; /* IV sense by default is set to 16 bit, in case of power Limiter it should be 12*/
		ti,vbat-mon = <0>; /* By default Vbat should be 0, in case os power limiter it should be 1*/

		vivo,impedance-min = <3145728>; /*speaker min impedance 6.0ohm*/
		vivo,impedance-max = <5242880>; /*speaker max impedance 10.0ohm*/
		vivo,frequency-min = <720>;
		vivo,frequency-max = <920>;
		vivo,Qt-min = <125>;
		status = "okay";
    };
};
/*vivo audio team add for speaker end*/

/* fengmingli add for usb start */
&usb3_tune {
	u2_vrt_ref = <0x7>;
	u2_term_ref = <0x5>;
	u2_enhance = <0x2>;
	u2_vrt_ref_host = <0x5>;
	u2_term_ref_host = <0x6>;
	u2_enhance_host = <0x2>;
};
/* fengmingli add for usb end */

&boards_version {
	pinctrl-names = "default";
	pinctrl-0 = <&board_version>;
	gpio_nums = <9>;
	gpios = <73 75 105 106 107 108 109 148 149>;
	gpios_start = <&pio 73 0>;
};

&board_info {
	vivo,vendor_project_name = "PD2079F_EX";
	vivo,vendor_project_cpu = "MT6785U";
	vivo,vendor_project_freq = "2.0";
	vivo,vendor_project_cpunum = <8>;
};

&tcard_sim_slot {
	pinctrl-names = "default";
	pinctrl-0 = <&card_detect>;
        factory-test,sim1-card;
        factory-test,sim2-card;
	//factory-test,tf-card;
	vivo,new_card_detect;
        card-detect-sim1,gpios = <&pio 140 0x0>;
        card-detect-sim2,gpios = <&pio 141 0x0>;
	//card-detect-tf-card,gpios = <&pio 18 0x0>;
};

&pio {
	board_version: hardware_board_version {
		pins_cmd0_dat {
			pinmux = <PINMUX_GPIO73__FUNC_GPIO73>;
			slew-rate = <0>;
			bias-pull-up = <11>;
		};
		pins_cmd1_dat {
			pinmux = <PINMUX_GPIO75__FUNC_GPIO75>;
			slew-rate = <0>;
			bias-pull-up = <11>;
		};
		pins_cmd2_dat {
			pinmux = <PINMUX_GPIO105__FUNC_GPIO105>;
			slew-rate = <0>;
			bias-pull-up = <11>;
		};
		pins_cmd3_dat {
			pinmux = <PINMUX_GPIO106__FUNC_GPIO106>;
			slew-rate = <0>;
			bias-pull-up = <11>;
		};
		pins_cmd4_dat {
			pinmux = <PINMUX_GPIO107__FUNC_GPIO107>;
			slew-rate = <0>;
			bias-pull-up = <11>;
		};
		pins_cmd5_dat {
			pinmux = <PINMUX_GPIO108__FUNC_GPIO108>;
			slew-rate = <0>;
			bias-pull-up = <11>;
		};
		pins_cmd6_dat {
			pinmux = <PINMUX_GPIO109__FUNC_GPIO109>;
			slew-rate = <0>;
			bias-pull-up = <11>;
		};
		pins_cmd7_dat {
			pinmux = <PINMUX_GPIO148__FUNC_GPIO148>;
			slew-rate = <0>;
			bias-pull-up = <11>;
		};
		pins_cmd8_dat {
			pinmux = <PINMUX_GPIO149__FUNC_GPIO149>;
			slew-rate = <0>;
			bias-pull-up = <11>;
		};
	};

	card_detect: card_sim_detect {
		pins_cmd0_dat {
			pinmux = <PINMUX_GPIO140__FUNC_MD_INT1_C2K_UIM0_HOT_PLUG>;
			slew-rate = <0>;
			bias-disable;
		};
		pins_cmd1_dat {
			pinmux = <PINMUX_GPIO141__FUNC_GPIO141>;
			slew-rate = <0>;
			bias-disable;
		};
		//pins_cmd2_dat {
		//	pinmux = <PINMUX_GPIO18__FUNC_GPIO18>;
		//	slew-rate = <0>;
		//	bias-disable;
		//};
	};
};
